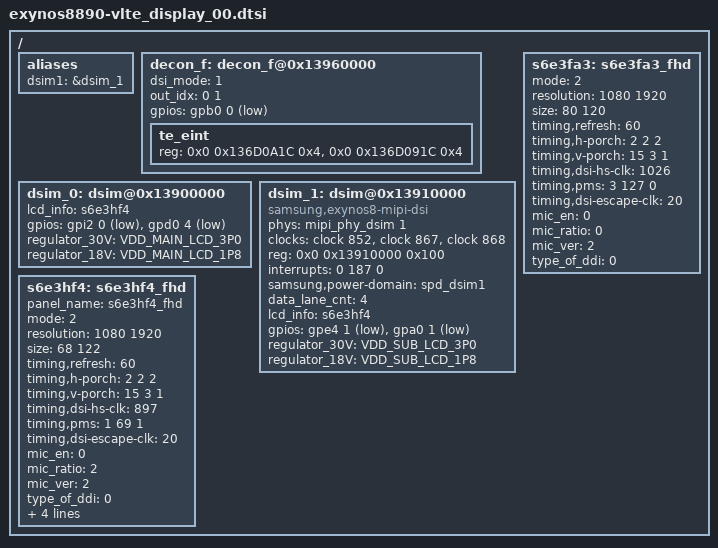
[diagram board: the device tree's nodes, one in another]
/*
 * SAMSUNG UNIVERSAL7420 board device tree source
 *
 * Copyright (c) 2014 Samsung Electronics Co., Ltd.
 *		http://www.samsung.com
 *
 * This program is free software; you can redistribute it and/or modify
 * it under the terms of the GNU General Public License version 2 as
 * published by the Free Software Foundation.
*/


/ {
	aliases {
		dsim1 = &dsim_1;
	};

		decon_f: decon_f@0x13960000 {
		dsi_mode = <1>;
		out_idx = <0 1>;
		/* EINT for TE */
		gpios = <&gpb0 0 0xf>;
		te_eint {
			/* NWEINT_GPB0_PEND(GPB0_0), NWEINT_GPB0_MASK(GPB0_0) */
			reg = <0x0 0x136D0A1C 0x4>, <0x0 0x136D091C 0x4>;
		};
	};

	dsim_0: dsim@0x13900000 {
		lcd_info = <&s6e3hf4>;
		/* lcd reset, power */
		gpios = <&gpi2 0 0x1>, <&gpd0 4 0x1>;
		/* gpios = <&gpi2 0 0x1>; */
		regulator_30V = "VDD_MAIN_LCD_3P0";
		regulator_18V = "VDD_MAIN_LCD_1P8";
	};
		
	dsim_1: dsim@0x13910000 {
		compatible = "samsung,exynos8-mipi-dsi";
		
		phys = <&mipi_phy_dsim 1>;
		phy-names = "dsim_dphy";		
		clocks = <&clock 852>, <&clock 867>, <&clock 868>;
		clock-names = "dsim_pclk", "dphy_escclk", "dphy_byteclk";
		reg = <0x0 0x13910000 0x100>;
		interrupts = <0 187 0>;
		samsung,power-domain = <&spd_dsim1>;

		/* number of using data lane */
		data_lane_cnt = <4>;
		
		lcd_info = <&s6e3hf4>;
		/* lcd reset, power */
		gpios = <&gpe4 1 0x1>, <&gpa0 1 0x1>;
		/* gpios = <&gpe4 1 0x1>; */
		regulator_30V = "VDD_SUB_LCD_3P0";
		regulator_18V = "VDD_SUB_LCD_1P8";
	};
	

	s6e3fa3: s6e3fa3_fhd {
		mode = <2>;		/* 0: video mode, 1: DP command mode, 2: MIPI command mode */
		resolution = <1080 1920>;
		size = <80 120>;
		timing,refresh = <60>;
		timing,h-porch = <2 2 2>;
		timing,v-porch = <15 3 1>;
		timing,dsi-hs-clk = <1026>;
		timing,pms = <3 127 0>;
		timing,dsi-escape-clk = <20>;
		mic_en = <0>;		/* 0: Disable, 1: Enable */
		mic_ratio = <0>;	/* 0: 1/2 mic, 1: 1/3 mic */
		mic_ver = <2>;		/* 0: mic v1.1, 1: v1.2, 2: v2.0 */
		type_of_ddi = <0>;	/* 0: Samsung Mobile, 1: MAGNA, 2: Normal(Etc) */
	};

	s6e3hf4: s6e3hf4_fhd {
		panel_name = "s6e3hf4_fhd";
		mode = <2>;		/* 0: video mode, 1: DP command mode, 2: MIPI command mode */
		resolution = <1080 1920>;
		size = <68 122>;
		timing,refresh = <60>;
		timing,h-porch = <2 2 2>;
		timing,v-porch = <15 3 1>;
		timing,dsi-hs-clk = <897>;
		timing,pms = <1 69 1>;
		timing,dsi-escape-clk = <20>;
		mic_en = <0>;		/* 0: Disable, 1: Enable */
		mic_ratio = <2>;	/* 0: 1/2 mic, 1: 1/3 mic */
		mic_ver = <2>;		/* 0: mic v1.1, 1: v1.2, 2: v2.0 */
		type_of_ddi = <0>;	/* 0: Samsung Mobile, 1: MAGNA, 2: Normal(Etc) */
		dsc_en = <1>;		/* 0: Disable, 1: Enable */
		dsc_cnt = <1>;		/* used DSC count */
		dsc_slice_num = <2>;	/* count of dsc slice */
		dsc_slice_h = <32>;	/* height of dsc slice */
	};
};
